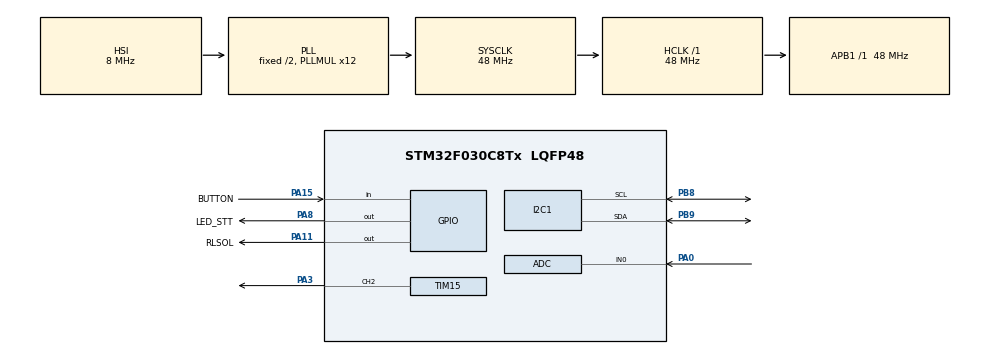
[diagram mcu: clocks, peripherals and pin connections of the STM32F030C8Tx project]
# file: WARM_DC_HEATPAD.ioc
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ADC.ClockPrescaler=ADC_CLOCK_SYNC_PCLK_DIV4
ADC.ContinuousConvMode=ENABLE
ADC.DMAContinuousRequests=ENABLE
ADC.EnableAnalogWatchDog=false
ADC.SamplingTime=ADC_SAMPLETIME_239CYCLES_5
Dma.ADC.0.Direction=DMA_PERIPH_TO_MEMORY
Dma.ADC.0.Instance=DMA1_Channel1
Dma.ADC.0.MemDataAlignment=DMA_MDATAALIGN_HALFWORD
Dma.ADC.0.MemInc=DMA_MINC_ENABLE
Dma.ADC.0.Mode=DMA_CIRCULAR
Dma.ADC.0.PeriphDataAlignment=DMA_PDATAALIGN_HALFWORD
Dma.ADC.0.PeriphInc=DMA_PINC_DISABLE
Dma.ADC.0.Priority=DMA_PRIORITY_LOW
Dma.Request0=ADC
IWDG.Prescaler=IWDG_PRESCALER_64
Mcu.Family=STM32F0
Mcu.Name=STM32F030C8Tx
Mcu.Package=LQFP48
NVIC.DMA1_Channel1_IRQn=true\:0\:0\:false\:false\:true\:false\:true\:true
PA0.Mode=IN0
PA0.Signal=ADC_IN0
PA11.GPIO_Label=RLSOL
PA11.GPIO_PuPd=GPIO_PULLDOWN
PA11.Signal=GPIO_Output
PA13.Mode=Serial_Wire
PA13.Signal=SYS_SWDIO
PA14.Mode=Serial_Wire
PA14.Signal=SYS_SWCLK
PA15.GPIO_Label=BUTTON
PA15.GPIO_PuPd=GPIO_PULLUP
PA15.Signal=GPIO_Input
PA3.Signal=S_TIM15_CH2
PA8.GPIO_Label=LED_STT
PA8.GPIO_ModeDefaultOutputPP=GPIO_MODE_OUTPUT_PP
PA8.GPIO_PuPd=GPIO_PULLDOWN
PA8.Signal=GPIO_Output
PB8.GPIO_Pu=GPIO_PULLUP
PB8.Mode=I2C
PB8.Signal=I2C1_SCL
PB9.GPIO_Pu=GPIO_PULLUP
PB9.Mode=I2C
PB9.Signal=I2C1_SDA
ProjectManager.HeapSize=0x200
ProjectManager.StackSize=0x400
ProjectManager.TargetToolchain=STM32CubeIDE
RCC.AHBFreq_Value=48000000
RCC.APB1Freq_Value=48000000
RCC.APB1TimFreq_Value=48000000
RCC.HCLKFreq_Value=48000000
RCC.PLLMUL=RCC_PLL_MUL12
RCC.SYSCLKFreq_VALUE=48000000
RCC.SYSCLKSource=RCC_SYSCLKSOURCE_PLLCLK
SH.S_TIM15_CH2.0=TIM15_CH2,PWM Generation2 CH2
TIM15.Channel-PWM\ Generation2\ CH2=TIM_CHANNEL_2
TIM15.OCPolarity_2=TIM_OCPOLARITY_LOW
TIM15.Period=999
TIM15.Prescaler=48
VP_IWDG_VS_IWDG.Mode=IWDG_Activate
VP_TIM15_VS_ClockSourceINT.Mode=Internal
board=custom

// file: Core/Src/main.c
/* USER CODE BEGIN Header */
/**
 ******************************************************************************
 * @file           : main.c
 * @brief          : Main program body
 ******************************************************************************
 * @attention
 *
 * <h2><center>&copy; Copyright (c) 2022 STMicroelectronics.
 * All rights reserved.</center></h2>
 *
 * This software component is licensed by ST under BSD 3-Clause license,
 * the "License"; You may not use this file except in compliance with the
 * License. You may obtain a copy of the License at:
 *                        opensource.org/licenses/BSD-3-Clause
 *
 ******************************************************************************
 */
/* USER CODE END Header */
#include "main.h"

ADC_HandleTypeDef hadc;
DMA_HandleTypeDef hdma_adc;

I2C_HandleTypeDef hi2c1;

IWDG_HandleTypeDef hiwdg;

TIM_HandleTypeDef htim15;

void SystemClock_Config(void);
static void MX_GPIO_Init(void);
static void MX_DMA_Init(void);
static void MX_IWDG_Init(void);
static void MX_ADC_Init(void);
static void MX_I2C1_Init(void);
static void MX_TIM15_Init(void);

int main(void)
{

  /* MCU Configuration--------------------------------------------------------*/

  /* Reset of all peripherals, Initializes the Flash interface and the Systick. */
  HAL_Init();

  /* Configure the system clock */
  SystemClock_Config();

  /* Initialize all configured peripherals */
  MX_GPIO_Init();
  MX_DMA_Init();
  MX_IWDG_Init();
  MX_ADC_Init();
  MX_I2C1_Init();
  MX_TIM15_Init();
  /* USER CODE BEGIN 2 */
  heatCtrlInit();
  /* USER CODE END 2 */

  /* Infinite loop */
  /* USER CODE BEGIN WHILE */

  //Tan so IWDG = 40 khz,IWDG_PRESCALER_32,indow : 4095 => time = 3.276 s
  _MCU_WDT_Init();
  while(1) {
      _MCU_WDT_Refresh();
    /* USER CODE END WHILE */

    /* USER CODE BEGIN 3 */
      heatCtrlLoop();
  }
  /* USER CODE END 3 */
}

void SystemClock_Config(void)
{
  RCC_OscInitTypeDef RCC_OscInitStruct = {0};
  RCC_ClkInitTypeDef RCC_ClkInitStruct = {0};
  RCC_PeriphCLKInitTypeDef PeriphClkInit = {0};

  /** Initializes the RCC Oscillators according to the specified parameters
  * in the RCC_OscInitTypeDef structure.
  */
  RCC_OscInitStruct.OscillatorType = RCC_OSCILLATORTYPE_HSI|RCC_OSCILLATORTYPE_LSI;
  RCC_OscInitStruct.HSIState = RCC_HSI_ON;
  RCC_OscInitStruct.HSICalibrationValue = RCC_HSICALIBRATION_DEFAULT;
  RCC_OscInitStruct.LSIState = RCC_LSI_ON;
  RCC_OscInitStruct.PLL.PLLState = RCC_PLL_ON;
  RCC_OscInitStruct.PLL.PLLSource = RCC_PLLSOURCE_HSI;
  RCC_OscInitStruct.PLL.PLLMUL = RCC_PLL_MUL12;
  RCC_OscInitStruct.PLL.PREDIV = RCC_PREDIV_DIV1;
  if (HAL_RCC_OscConfig(&RCC_OscInitStruct) != HAL_OK)
  {
    Error_Handler();
  }

  /** Initializes the CPU, AHB and APB buses clocks
  */
  RCC_ClkInitStruct.ClockType = RCC_CLOCKTYPE_HCLK|RCC_CLOCKTYPE_SYSCLK
                              |RCC_CLOCKTYPE_PCLK1;
  RCC_ClkInitStruct.SYSCLKSource = RCC_SYSCLKSOURCE_PLLCLK;
  RCC_ClkInitStruct.AHBCLKDivider = RCC_SYSCLK_DIV1;
  RCC_ClkInitStruct.APB1CLKDivider = RCC_HCLK_DIV1;

  if (HAL_RCC_ClockConfig(&RCC_ClkInitStruct, FLASH_LATENCY_1) != HAL_OK)
  {
    Error_Handler();
  }
  PeriphClkInit.PeriphClockSelection = RCC_PERIPHCLK_I2C1;
  PeriphClkInit.I2c1ClockSelection = RCC_I2C1CLKSOURCE_HSI;
  if (HAL_RCCEx_PeriphCLKConfig(&PeriphClkInit) != HAL_OK)
  {
    Error_Handler();
  }
}

static void MX_ADC_Init(void)
{

  ADC_ChannelConfTypeDef sConfig = {0};

  /** Configure the global features of the ADC (Clock, Resolution, Data Alignment and number of conversion)
  */
  hadc.Instance = ADC1;
  hadc.Init.ClockPrescaler = ADC_CLOCK_SYNC_PCLK_DIV4;
  hadc.Init.Resolution = ADC_RESOLUTION_12B;
  hadc.Init.DataAlign = ADC_DATAALIGN_RIGHT;
  hadc.Init.ScanConvMode = ADC_SCAN_DIRECTION_FORWARD;
  hadc.Init.EOCSelection = ADC_EOC_SINGLE_CONV;
  hadc.Init.LowPowerAutoWait = DISABLE;
  hadc.Init.LowPowerAutoPowerOff = DISABLE;
  hadc.Init.ContinuousConvMode = ENABLE;
  hadc.Init.DiscontinuousConvMode = DISABLE;
  hadc.Init.ExternalTrigConv = ADC_SOFTWARE_START;
  hadc.Init.ExternalTrigConvEdge = ADC_EXTERNALTRIGCONVEDGE_NONE;
  hadc.Init.DMAContinuousRequests = ENABLE;
  hadc.Init.Overrun = ADC_OVR_DATA_PRESERVED;
  if (HAL_ADC_Init(&hadc) != HAL_OK)
  {
    Error_Handler();
  }

  /** Configure for the selected ADC regular channel to be converted.
  */
  sConfig.Channel = ADC_CHANNEL_0;
  sConfig.Rank = ADC_RANK_CHANNEL_NUMBER;
  sConfig.SamplingTime = ADC_SAMPLETIME_239CYCLES_5;
  if (HAL_ADC_ConfigChannel(&hadc, &sConfig) != HAL_OK)
  {
    Error_Handler();
  }

}

static void MX_I2C1_Init(void)
{

  hi2c1.Instance = I2C1;
  hi2c1.Init.Timing = 0x2000090E;
  hi2c1.Init.OwnAddress1 = 0;
  hi2c1.Init.AddressingMode = I2C_ADDRESSINGMODE_7BIT;
  hi2c1.Init.DualAddressMode = I2C_DUALADDRESS_DISABLE;
  hi2c1.Init.OwnAddress2 = 0;
  hi2c1.Init.OwnAddress2Masks = I2C_OA2_NOMASK;
  hi2c1.Init.GeneralCallMode = I2C_GENERALCALL_DISABLE;
  hi2c1.Init.NoStretchMode = I2C_NOSTRETCH_DISABLE;
  if (HAL_I2C_Init(&hi2c1) != HAL_OK)
  {
    Error_Handler();
  }

  /** Configure Analogue filter
  */
  if (HAL_I2CEx_ConfigAnalogFilter(&hi2c1, I2C_ANALOGFILTER_ENABLE) != HAL_OK)
  {
    Error_Handler();
  }

  /** Configure Digital filter
  */
  if (HAL_I2CEx_ConfigDigitalFilter(&hi2c1, 0) != HAL_OK)
  {
    Error_Handler();
  }

}

static void MX_IWDG_Init(void)
{

  hiwdg.Instance = IWDG;
  hiwdg.Init.Prescaler = IWDG_PRESCALER_64;
  hiwdg.Init.Window = 4095;
  hiwdg.Init.Reload = 4095;
  if (HAL_IWDG_Init(&hiwdg) != HAL_OK)
  {
    Error_Handler();
  }

}

static void MX_TIM15_Init(void)
{

  TIM_ClockConfigTypeDef sClockSourceConfig = {0};
  TIM_MasterConfigTypeDef sMasterConfig = {0};
  TIM_OC_InitTypeDef sConfigOC = {0};
  TIM_BreakDeadTimeConfigTypeDef sBreakDeadTimeConfig = {0};

  htim15.Instance = TIM15;
  htim15.Init.Prescaler = 48;
  htim15.Init.CounterMode = TIM_COUNTERMODE_UP;
  htim15.Init.Period = 999;
  htim15.Init.ClockDivision = TIM_CLOCKDIVISION_DIV1;
  htim15.Init.RepetitionCounter = 0;
  htim15.Init.AutoReloadPreload = TIM_AUTORELOAD_PRELOAD_DISABLE;
  if (HAL_TIM_Base_Init(&htim15) != HAL_OK)
  {
    Error_Handler();
  }
  sClockSourceConfig.ClockSource = TIM_CLOCKSOURCE_INTERNAL;
  if (HAL_TIM_ConfigClockSource(&htim15, &sClockSourceConfig) != HAL_OK)
  {
    Error_Handler();
  }
  if (HAL_TIM_PWM_Init(&htim15) != HAL_OK)
  {
    Error_Handler();
  }
  sMasterConfig.MasterOutputTrigger = TIM_TRGO_RESET;
  sMasterConfig.MasterSlaveMode = TIM_MASTERSLAVEMODE_DISABLE;
  if (HAL_TIMEx_MasterConfigSynchronization(&htim15, &sMasterConfig) != HAL_OK)
  {
    Error_Handler();
  }
  sConfigOC.OCMode = TIM_OCMODE_PWM1;
  sConfigOC.Pulse = 0;
  sConfigOC.OCPolarity = TIM_OCPOLARITY_LOW;
  sConfigOC.OCNPolarity = TIM_OCNPOLARITY_HIGH;
  sConfigOC.OCFastMode = TIM_OCFAST_DISABLE;
  sConfigOC.OCIdleState = TIM_OCIDLESTATE_RESET;
  sConfigOC.OCNIdleState = TIM_OCNIDLESTATE_RESET;
  if (HAL_TIM_PWM_ConfigChannel(&htim15, &sConfigOC, TIM_CHANNEL_2) != HAL_OK)
  {
    Error_Handler();
  }
  sBreakDeadTimeConfig.OffStateRunMode = TIM_OSSR_DISABLE;
  sBreakDeadTimeConfig.OffStateIDLEMode = TIM_OSSI_DISABLE;
  sBreakDeadTimeConfig.LockLevel = TIM_LOCKLEVEL_OFF;
  sBreakDeadTimeConfig.DeadTime = 0;
  sBreakDeadTimeConfig.BreakState = TIM_BREAK_DISABLE;
  sBreakDeadTimeConfig.BreakPolarity = TIM_BREAKPOLARITY_HIGH;
  sBreakDeadTimeConfig.AutomaticOutput = TIM_AUTOMATICOUTPUT_DISABLE;
  if (HAL_TIMEx_ConfigBreakDeadTime(&htim15, &sBreakDeadTimeConfig) != HAL_OK)
  {
    Error_Handler();
  }
  HAL_TIM_MspPostInit(&htim15);

}

static void MX_DMA_Init(void)
{

  /* DMA controller clock enable */
  __HAL_RCC_DMA1_CLK_ENABLE();

  /* DMA interrupt init */
  /* DMA1_Channel1_IRQn interrupt configuration */
  HAL_NVIC_SetPriority(DMA1_Channel1_IRQn, 0, 0);
  HAL_NVIC_EnableIRQ(DMA1_Channel1_IRQn);

}

static void MX_GPIO_Init(void)
{
  GPIO_InitTypeDef GPIO_InitStruct = {0};

  /* GPIO Ports Clock Enable */
  __HAL_RCC_GPIOC_CLK_ENABLE();
  __HAL_RCC_GPIOF_CLK_ENABLE();
  __HAL_RCC_GPIOA_CLK_ENABLE();
  __HAL_RCC_GPIOB_CLK_ENABLE();

  /*Configure GPIO pin Output Level */
  HAL_GPIO_WritePin(GPIOA, LED_STT_Pin|RLSOL_Pin, GPIO_PIN_RESET);

  /*Configure GPIO pins : PC13 PC14 PC15 */
  GPIO_InitStruct.Pin = GPIO_PIN_13|GPIO_PIN_14|GPIO_PIN_15;
  GPIO_InitStruct.Mode = GPIO_MODE_ANALOG;
  GPIO_InitStruct.Pull = GPIO_NOPULL;
  HAL_GPIO_Init(GPIOC, &GPIO_InitStruct);

  /*Configure GPIO pins : PF0 PF1 PF6 PF7 */
  GPIO_InitStruct.Pin = GPIO_PIN_0|GPIO_PIN_1|GPIO_PIN_6|GPIO_PIN_7;
  GPIO_InitStruct.Mode = GPIO_MODE_ANALOG;
  GPIO_InitStruct.Pull = GPIO_NOPULL;
  HAL_GPIO_Init(GPIOF, &GPIO_InitStruct);

  /*Configure GPIO pins : PA1 PA2 PA4 PA5
                           PA6 PA7 PA9 PA10
                           PA12 */
  GPIO_InitStruct.Pin = GPIO_PIN_1|GPIO_PIN_2|GPIO_PIN_4|GPIO_PIN_5
                          |GPIO_PIN_6|GPIO_PIN_7|GPIO_PIN_9|GPIO_PIN_10
                          |GPIO_PIN_12;
  GPIO_InitStruct.Mode = GPIO_MODE_ANALOG;
  GPIO_InitStruct.Pull = GPIO_NOPULL;
  HAL_GPIO_Init(GPIOA, &GPIO_InitStruct);

  /*Configure GPIO pins : PB0 PB1 PB2 PB10
                           PB11 PB12 PB13 PB14
                           PB15 PB3 PB4 PB5
                           PB6 PB7 */
  GPIO_InitStruct.Pin = GPIO_PIN_0|GPIO_PIN_1|GPIO_PIN_2|GPIO_PIN_10
                          |GPIO_PIN_11|GPIO_PIN_12|GPIO_PIN_13|GPIO_PIN_14
                          |GPIO_PIN_15|GPIO_PIN_3|GPIO_PIN_4|GPIO_PIN_5
                          |GPIO_PIN_6|GPIO_PIN_7;
  GPIO_InitStruct.Mode = GPIO_MODE_ANALOG;
  GPIO_InitStruct.Pull = GPIO_NOPULL;
  HAL_GPIO_Init(GPIOB, &GPIO_InitStruct);

  /*Configure GPIO pins : LED_STT_Pin RLSOL_Pin */
  GPIO_InitStruct.Pin = LED_STT_Pin|RLSOL_Pin;
  GPIO_InitStruct.Mode = GPIO_MODE_OUTPUT_PP;
  GPIO_InitStruct.Pull = GPIO_PULLDOWN;
  GPIO_InitStruct.Speed = GPIO_SPEED_FREQ_LOW;
  HAL_GPIO_Init(GPIOA, &GPIO_InitStruct);

  /*Configure GPIO pin : BUTTON_Pin */
  GPIO_InitStruct.Pin = BUTTON_Pin;
  GPIO_InitStruct.Mode = GPIO_MODE_INPUT;
  GPIO_InitStruct.Pull = GPIO_PULLUP;
  HAL_GPIO_Init(BUTTON_GPIO_Port, &GPIO_InitStruct);

}

void Error_Handler(void)
{
	__disable_irq();
	while(1) {
	}
}
